# STM32F412 register map
File version: 1.7
CPU: CM4 r0p1, little endian, MPU, FPU, 4 interrupt priority bits
Registers are 32-bit, read-write, reset 0x0 unless marked. A register's access mark holds for its fields unless they carry their own. Offsets are from the block's base; [hi:lo] are bit positions; {n}, {i} and the like mark numbered series; 'fields as' and 'values as' point back to an identical list.

## IWDG — Independent watchdog
Base 0x40003000
0x00 KR 16-bit wo — Key register
  [15:0] KEY — Key value
    0x5555=Unlock (Enable access to PR, RLR and WINR registers); 0xAAAA=Feed watchdog with RLR register value; 0xCCCC=Start the watchdog
0x04 PR 16-bit — Prescaler register
  [2:0] PR — Prescaler divider
    0=DivideBy4 (Divider /4); 1=DivideBy8 (Divider /8); 2=DivideBy16 (Divider /16); 3=DivideBy32 (Divider /32); 4=DivideBy64 (Divider /64); 5=DivideBy128 (Divider /128); other=DivideBy256 (Divider /256)
0x08 RLR 16-bit reset 0xFFF — Reload register
  [11:0] RL — Watchdog counter reload value
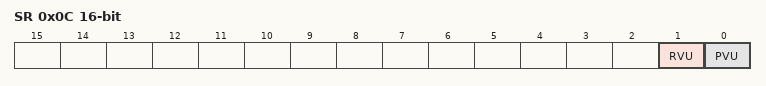
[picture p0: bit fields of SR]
0x0C SR 16-bit ro — Status register
  [1] RVU — Watchdog counter reload value update
  [0] PVU — Watchdog prescaler value update

## SYSCFG — System configuration controller
Base 0x40013800
0x00 MEMRMP — memory remap register
  [1:0] MEM_MODE
    0=Main Flash memory mapped at 0x0000 0000; 1=System Flash memory mapped at 0x0000 0000; 2=FSMC Bank1 (NOR/PSRAM 1 and 2) mapped at 0x0000 0000; 3=Embedded SRAM mapped at 0x0000 0000
0x04 PMC — peripheral mode configuration register
  [16] ADC1DC2
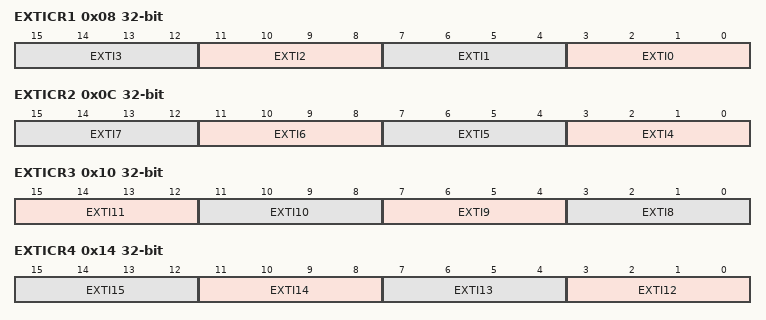
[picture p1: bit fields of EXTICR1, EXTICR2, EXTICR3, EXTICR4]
0x08 EXTICR1 — external interrupt configuration register 1
  [all] fields
    0=PA (Select PAx as the source input for the EXTIx external interrupt); 1=PB (Select PBx as the source input for the EXTIx external interrupt); 2=PC (Select PCx as the source input for the EXTIx external interrupt); 3=PD (Select PDx as the source input for the EXTIx external interrupt); 4=PE (Select PEx as the source input for the EXTIx external interrupt); 5=PF (Select PFx as the source input for the EXTIx external interrupt); 6=PG (Select PGx as the source input for the EXTIx external interrupt)
  [4n+3:4n] EXTI{n} (n=0..3) — EXTI x configuration (x = 0 to 3)
0x0C EXTICR2 — external interrupt configuration register 2
  [all] fields
    values as the fields of EXTICR1
  [4n-13:4n-16] EXTI{n} (n=4..7) — EXTI x configuration (x = 4 to 7)
0x10 EXTICR3 — external interrupt configuration register 3
  [all] fields
    values as the fields of EXTICR1
  [15:12] EXTI11 — EXTI x configuration (x = 8 to 11)
  [11:8] EXTI10
  [7:4] EXTI9 — EXTI x configuration (x = 8 to 11)
  [3:0] EXTI8 — EXTI x configuration (x = 8 to 11)
0x14 EXTICR4 — external interrupt configuration register 4
  [all] fields
    values as the fields of EXTICR1
  [4n-45:4n-48] EXTI{n} (n=12..15) — EXTI x configuration (x = 12 to 15)
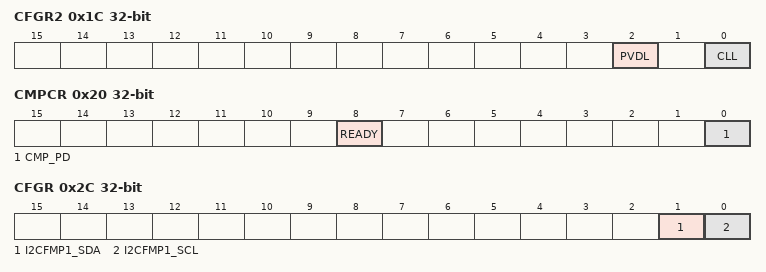
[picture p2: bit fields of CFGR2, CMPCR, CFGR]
0x1C CFGR2 — ADC Common status register
  [2] PVDL — PVD lock
    0=NotConnected (PVD interrupt not connected to TIM1 Break input. PVDE and PVDS[2:0] can be read and modified); 1=Connected (PVD interrupt connected to TIM1 Break input. PVDE and PVDS[2:0] are read-only)
  [0] CLL — core lockup lock
    0=NotConnected (Cortex-M4 LOCKUP output not connected to TIM1 Break input); 1=Connected (Cortex-M4 LOCKUP output connected to TIM1 Break input)
0x20 CMPCR ro — Compensation cell control register
  [8] READY
    0=NotReady (I/O compensation cell not ready); 1=Ready (I/O compensation cell ready)
  [0] CMP_PD rw — Compensation cell power-down
    0=PowerDown (I/O compensation cell power-down mode); 1=Enabled (I/O compensation cell enabled)
0x2C CFGR — Configuration register
  [1] I2CFMP1_SDA — I2C4SDA
    0=Clear; 1=Forced (forces FM+ drive capability on I2CFMP1_SDA pin)
  [0] I2CFMP1_SCL — I2C4SCL
    0=Clear; 1=Forced (forces FM+ drive capability on I2CFMP1_SCL pin)

## WWDG — Window watchdog
Base 0x40002C00
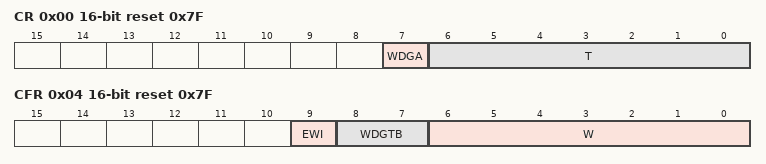
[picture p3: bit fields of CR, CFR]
0x00 CR 16-bit reset 0x7F — Control register
  [7] WDGA — Activation bit
    0=Disabled (Watchdog disabled); 1=Enabled (Watchdog enabled)
  [6:0] T — 7-bit counter (MSB to LSB)
0x04 CFR 16-bit reset 0x7F — Configuration register
  [9] EWI — Early wakeup interrupt
    on write: 1=Enable (interrupt occurs whenever the counter reaches the value 0x40)
  [8:7] WDGTB — Timer base
    0=Div1 (Counter clock (PCLK1 div 4096) div 1); 1=Div2 (Counter clock (PCLK1 div 4096) div 2); 2=Div4 (Counter clock (PCLK1 div 4096) div 4); 3=Div8 (Counter clock (PCLK1 div 4096) div 8)
  [6:0] W — 7-bit window value
0x08 SR 16-bit — Status register
  [0] EWIF write-0-clears — Early wakeup interrupt flag
    on read: 0=Finished (The EWI Interrupt Service Routine has been serviced); 1=Pending (The EWI Interrupt Service Routine has been triggered) | on write: 0=Finished (The EWI Interrupt Service Routine has been serviced)
